AUTOSAR XML (schema 4-2-1)
standard types defined: boolean, uint16, uint8
package /VehicleProject
  system System
package /NM
  nm config NmConfig: can-nm-cluster-coupling=coupled-cluster=CAN00_CAN
    can nm cluster CAN00_CAN: communication-cluster=Comfort, nm-channel-id=0, nm-msg-cycle-time=2, nm-network-timeout=1, nm-repeat-message-time=0.4, nm-user-data-length=5, nm-wait-bus-sleep-time=0.75
      4 x can nm node, all with nm-msg-cycle-offset=0.01, nm-msg-reduced-time=0.05, nm-range-config={lower-can-id=1280, upper-can-id=1407}:
        Console: controller=Console/CT_CAN00, nm-if-ecu=Console_CAN, nm-node-id=-230, tx-nm-pdu=NM_Console
        DOOR_le: controller=DOOR_le/CT_CAN00, nm-if-ecu=DOOR_le_CAN, nm-node-id=-229, rx-nm-pdu=[NM_Console, NM_DOORright, NM_Gateway], tx-nm-pdu=NM_DOORleft
        DOOR_ri: controller=DOOR_ri/CT_CAN00, nm-if-ecu=DOOR_ri_CAN, nm-node-id=-228, rx-nm-pdu=[NM_Console, NM_DOORleft, NM_Gateway], tx-nm-pdu=NM_DOORright
        Gateway: controller=Gateway/CT_CAN00, nm-if-ecu=Gateway_CAN, nm-node-id=-227, rx-nm-pdu=[NM_Console, NM_DOORleft, NM_DOORright], tx-nm-pdu=NM_Gateway
    nm-if-ecus:
      4 x nm ecu, all with nm-node-id-enabled=true, nm-user-data-enabled=true:
        Console_CAN: ecu-instance=Console
        DOOR_le_CAN: ecu-instance=DOOR_le
        DOOR_ri_CAN: ecu-instance=DOOR_ri
        Gateway_CAN: ecu-instance=Gateway
package /TP
  can tp config CAN00_CAN: communication-cluster=Comfort
    can tp channel TPCH: channel-id=0, channel-mode=FULL-DUPLEX-MODE
package /Cluster
  can cluster Comfort: baudrate=500000, protocol-name=CAN  # democomfort | CAN communication matrix for body electronics*******************************************************implemented: turn lights, warning lights, windows
    can physical channel CHNL: comm-connectors=[Console/CN_CAN00, Dashboard/CN_CAN00, DOOR_le/CN_CAN00, DOOR_ri/CN_CAN00, Gateway/CN_CAN00]
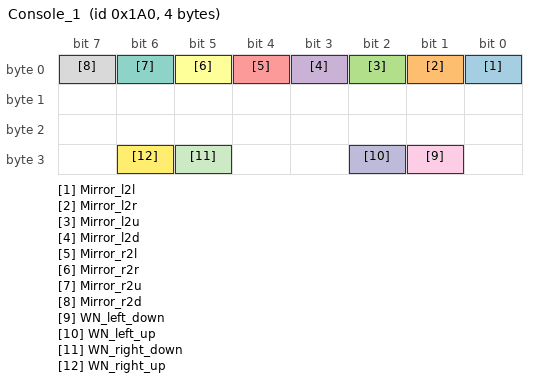
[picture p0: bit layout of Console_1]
      frame Console_1: id 0x1A0, from Console, to DOOR_le DOOR_ri, frame-length=4, can-addressing-mode=STANDARD, can-frame-tx-behavior=CAN-20
        pdu Console_1: length=4, minimum-delay=0.001, transmission-mode-false-timing=cyclic-timing={time-offset=0, time-period=0.02}, transmission-mode-true-timing=cyclic-timing={time-offset=0, time-period=0.02}, unused-bit-pattern=0
          signal Mirror_l2l: start 0, 1 bit, little-endian, init-value=0, base-type=boolean, compu {phys=raw for raw 0..1}, transfer-property=PENDING
          signal Mirror_l2r: start 1, 1 bit, little-endian, init-value=0, base-type=boolean, compu {phys=raw for raw 0..1}, transfer-property=PENDING
          signal Mirror_l2u: start 2, 1 bit, little-endian, init-value=0, base-type=boolean, compu {phys=raw for raw 0..1}, transfer-property=PENDING
          signal Mirror_l2d: start 3, 1 bit, little-endian, init-value=0, base-type=boolean, compu {phys=raw for raw 0..1}, transfer-property=PENDING
          signal Mirror_r2l: start 4, 1 bit, little-endian, init-value=0, base-type=boolean, compu {phys=raw for raw 0..1}, transfer-property=PENDING
          signal Mirror_r2r: start 5, 1 bit, little-endian, init-value=0, base-type=boolean, compu {phys=raw for raw 0..1}, transfer-property=PENDING
          signal Mirror_r2u: start 6, 1 bit, little-endian, init-value=0, base-type=boolean, compu {phys=raw for raw 0..1}, transfer-property=PENDING
          signal Mirror_r2d: start 7, 1 bit, little-endian, init-value=0, base-type=boolean, compu {phys=raw for raw 0..1}, transfer-property=PENDING
          signal WN_left_down: start 25, 1 bit, little-endian, init-value=0, base-type=boolean, compu {phys=raw for raw 0..1}, transfer-property=PENDING, to DOOR_le
          signal WN_left_up: start 26, 1 bit, little-endian, init-value=0, base-type=boolean, compu {phys=raw for raw 0..1}, transfer-property=PENDING, to DOOR_le
          signal WN_right_down: start 29, 1 bit, little-endian, init-value=0, base-type=boolean, compu {phys=raw for raw 0..1}, transfer-property=PENDING, to DOOR_ri
          signal WN_right_up: start 30, 1 bit, little-endian, init-value=0, base-type=boolean, compu {phys=raw for raw 0..1}, transfer-property=PENDING, to DOOR_ri
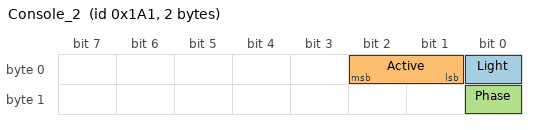
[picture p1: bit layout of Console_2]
      frame Console_2: id 0x1A1, from Console, frame-length=2, can-addressing-mode=STANDARD, can-frame-tx-behavior=CAN-20
        pdu Console_2: length=2, minimum-delay=0.001, transmission-mode-condition{data-filter={data-filter-type=MASKED-NEW-DIFFERS-X, mask=1, x=0}, i-signal-in-i-pdu=Light}, transmission-mode-false-timing=cyclic-timing=time-period=0.5, transmission-mode-true-timing=cyclic-timing=time-period=0.1, unused-bit-pattern=0
          signal Light: start 0, 1 bit, little-endian, init-value=0, base-type=boolean, compu {phys=raw for raw 0..1}, transfer-property=PENDING
          signal Active: start 1, 2 bit, little-endian, init-value=0, base-type=uint8, compu {0=None, 1=Turn_right, 2=Turn_left, 3=Warning}, transfer-property=PENDING
          signal Phase: start 8, 1 bit, little-endian, init-value=0, base-type=boolean, compu {phys=raw for raw 0..1}, transfer-property=PENDING
      frame DebugMsg1: id 0x100, to Gateway, frame-length=8, can-addressing-mode=STANDARD, can-frame-tx-behavior=CAN-20
        pdu DebugMsg1: length=8, minimum-delay=0, unused-bit-pattern=0
          signal DebugMsg1: start 0, 64 bit, opaque, init-value=8 x 0, base-type=uint8_8_iso_8859_1, compu {phys=raw for raw 0..1.84467440737096e+19}, transfer-property=PENDING, to Gateway
      frame Diag_Request: id 0x700, frame-length=8, can-addressing-mode=STANDARD
      frame Diag_Response: id 0x600, frame-length=8, can-addressing-mode=STANDARD
        user defined pdu Diag_Response: length=8
      frame DiagRequest: id 0x606, to DOOR_le, frame-length=8, can-addressing-mode=STANDARD
        user defined pdu DiagRequest: length=8
      frame DiagResponse_DoorLeft: id 0x607, from DOOR_le, frame-length=8, can-addressing-mode=STANDARD
        user defined pdu DiagResponse_DoorLeft: length=8
      frame DiagResponse_Motor: id 0x601, from Gateway, frame-length=8, can-addressing-mode=STANDARD
        user defined pdu DiagResponse_Motor: length=8
      frame DOOR_l: id 0x1F0, from DOOR_le, frame-length=1, can-addressing-mode=STANDARD, can-frame-tx-behavior=CAN-20
        pdu DOOR_l: length=1, minimum-delay=0.001, transmission-mode-false-timing=cyclic-timing=time-period=0.03, transmission-mode-true-timing=cyclic-timing=time-period=0.03, unused-bit-pattern=0
          signal WN_Position_l: start 0, 8 bit, little-endian, init-value=0, base-type=uint8, compu {phys=raw for raw 0..255}, transfer-property=PENDING
      frame DOOR_r: id 0x1F1, from DOOR_ri, frame-length=1, can-addressing-mode=STANDARD, can-frame-tx-behavior=CAN-20
        pdu DOOR_r: length=1, minimum-delay=0.001, transmission-mode-false-timing=cyclic-timing=time-period=0.03, transmission-mode-true-timing=cyclic-timing=time-period=0.03, unused-bit-pattern=0
          signal WN_Position_r: start 0, 8 bit, little-endian, init-value=0, base-type=uint8, compu {phys=raw for raw 0..255}, transfer-property=PENDING
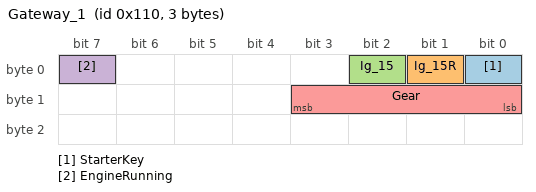
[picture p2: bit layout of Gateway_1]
      frame Gateway_1: id 0x110, from Gateway, to Console Dashboard, frame-length=3, can-addressing-mode=STANDARD, can-frame-tx-behavior=CAN-20
        pdu Gateway_1: length=3, minimum-delay=0.001, transmission-mode-false-timing=cyclic-timing=time-period=0.1, transmission-mode-true-timing=cyclic-timing=time-period=0.1, unused-bit-pattern=0
          signal StarterKey: start 0, 1 bit, little-endian, init-value=0, base-type=boolean, compu {phys=raw for raw 0..1}, transfer-property=PENDING, to Dashboard
          signal Ig_15R: start 1, 1 bit, little-endian, init-value=0, base-type=boolean, compu {phys=raw for raw 0..1}, transfer-property=PENDING, to Dashboard
          signal Ig_15: start 2, 1 bit, little-endian, init-value=0, base-type=boolean, compu {phys=raw for raw 0..1}, transfer-property=PENDING, to Console Dashboard
          signal EngineRunning: start 7, 1 bit, little-endian, init-value=0, base-type=boolean, compu {phys=raw for raw 0..1}, transfer-property=PENDING
          signal Gear: start 8, 4 bit, little-endian, init-value=0, base-type=uint8, compu {phys=raw for raw 0..15}, transfer-property=PENDING, to Dashboard
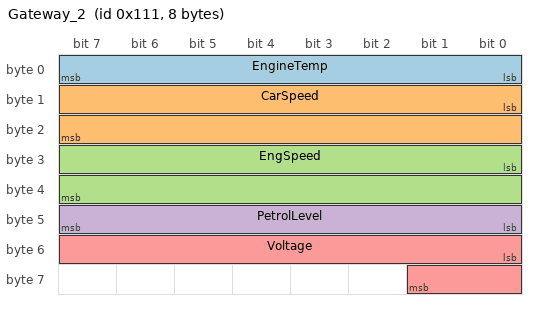
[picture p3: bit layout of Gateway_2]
      frame Gateway_2: id 0x111, from Gateway, to Dashboard, frame-length=8, can-addressing-mode=STANDARD, can-frame-tx-behavior=CAN-20
        pdu Gateway_2: length=8, minimum-delay=0.001, transmission-mode-false-timing={cyclic-timing=time-period=0.1, event-controlled-timing={number-of-repetitions=0, repetition-period=0}}, transmission-mode-true-timing={cyclic-timing=time-period=0.1, event-controlled-timing={number-of-repetitions=0, repetition-period=0}}, unused-bit-pattern=0
          transmission-mode-conditions:
            {data-filter={data-filter-type=MASKED-NEW-DIFFERS-MASKED-OLD, mask=65535}, i-signal-in-i-pdu=CarSpeed}
            {data-filter={data-filter-type=MASKED-NEW-DIFFERS-MASKED-OLD, mask=255}, i-signal-in-i-pdu=EngineTemp}
            {data-filter={data-filter-type=MASKED-NEW-DIFFERS-MASKED-OLD, mask=65535}, i-signal-in-i-pdu=EngSpeed}
            {data-filter={data-filter-type=MASKED-NEW-DIFFERS-MASKED-OLD, mask=255}, i-signal-in-i-pdu=PetrolLevel}
            {data-filter={data-filter-type=MASKED-NEW-DIFFERS-MASKED-OLD, mask=1023}, i-signal-in-i-pdu=Voltage}
          signal EngineTemp: start 0, 8 bit, little-endian, init-value=0, base-type=uint8, compu {phys=raw for raw 0..255; unit degC}, transfer-property=TRIGGERED, to Dashboard
          signal CarSpeed: start 8, 16 bit, little-endian, init-value=0, base-type=uint16, compu {phys=raw*0.5 for raw 0..65535; unit mph}, transfer-property=TRIGGERED, to Dashboard
          signal EngSpeed: start 24, 16 bit, little-endian, init-value=0, base-type=uint16, compu {phys=raw for raw 0..65535; unit rpm}, transfer-property=TRIGGERED, to Dashboard
          signal PetrolLevel: start 40, 8 bit, little-endian, init-value=0, base-type=uint8, compu {phys=raw for raw 0..255; unit l}, transfer-property=TRIGGERED, to Dashboard
          signal Voltage: start 48, 10 bit, little-endian, init-value=0, base-type=uint16, compu {phys=raw*0.1 for raw 0..1023; unit V}, transfer-property=TRIGGERED
      frame NM_Console: id 0x41A, from Console, to DOOR_le DOOR_ri Gateway Dashboard, frame-length=4, can-addressing-mode=STANDARD, can-frame-tx-behavior=CAN-20
        nm pdu NM_Console: length=4, unused-bit-pattern=0
      frame NM_DOORleft: id 0x41B, from DOOR_le, to DOOR_ri Gateway Console Dashboard, frame-length=4, can-addressing-mode=STANDARD, can-frame-tx-behavior=CAN-20
        nm pdu NM_DOORleft: length=4, unused-bit-pattern=0
      frame NM_DOORright: id 0x41C, from DOOR_ri, to DOOR_le Gateway Console Dashboard, frame-length=4, can-addressing-mode=STANDARD, can-frame-tx-behavior=CAN-20
        nm pdu NM_DOORright: length=4, unused-bit-pattern=0
      frame NM_Gateway: id 0x41D, from Gateway, to DOOR_le DOOR_ri Console Dashboard, frame-length=4, can-addressing-mode=STANDARD, can-frame-tx-behavior=CAN-20
        nm pdu NM_Gateway: length=4, unused-bit-pattern=0
      frame TP_Console: id 0x604, from Console, to Dashboard, frame-length=6, can-addressing-mode=STANDARD, can-frame-tx-behavior=CAN-20
        pdu TP_Console: length=6, minimum-delay=0, unused-bit-pattern=0
          signal TP_Console: start 0, 48 bit, opaque, init-value=6 x 0, base-type=uint8_6_iso_8859_1, compu {phys=raw for raw 0..281474976710655}, transfer-property=PENDING, to Dashboard
      frame TP_Dashboard: id 0x605, from Dashboard, to Console, frame-length=6, can-addressing-mode=STANDARD, can-frame-tx-behavior=CAN-20
        pdu TP_Dashboard: length=6, minimum-delay=0, unused-bit-pattern=0
          signal TP_Dashboard: start 0, 48 bit, opaque, init-value=6 x 0, base-type=uint8_6_iso_8859_1, compu {phys=raw for raw 0..281474976710655}, transfer-property=PENDING, to Console
package /ECU
  5 x ecu instance:
    Console: associated-com-i-pdu-group=[Console_Rx, Console_Tx]
      can communication controller CT_CAN00: can-controller-attributes=can-controller-configuration-requirements={max-number-of-time-quanta-per-bit=20, max-sample-point=81.25, min-number-of-time-quanta-per-bit=15, min-sample-point=80}
      can communication connector CN_CAN00: comm-controller=Console/CT_CAN00
    Dashboard: associated-com-i-pdu-group=[Dashboard_Rx, Dashboard_Tx]
      can communication controller CT_CAN00: can-controller-attributes=can-controller-configuration-requirements={max-number-of-time-quanta-per-bit=20, max-sample-point=81.25, min-number-of-time-quanta-per-bit=15, min-sample-point=80}
      can communication connector CN_CAN00: comm-controller=Dashboard/CT_CAN00
    DOOR_le: associated-com-i-pdu-group=[DOOR_le_Rx, DOOR_le_Tx]
      can communication controller CT_CAN00: can-controller-attributes=can-controller-configuration-requirements={max-number-of-time-quanta-per-bit=20, max-sample-point=81.25, min-number-of-time-quanta-per-bit=15, min-sample-point=80}
      can communication connector CN_CAN00: comm-controller=DOOR_le/CT_CAN00
    DOOR_ri: associated-com-i-pdu-group=[DOOR_ri_Rx, DOOR_ri_Tx]
      can communication controller CT_CAN00: can-controller-attributes=can-controller-configuration-requirements={max-number-of-time-quanta-per-bit=20, max-sample-point=81.25, min-number-of-time-quanta-per-bit=15, min-sample-point=80}
      can communication connector CN_CAN00: comm-controller=DOOR_ri/CT_CAN00
    Gateway: associated-com-i-pdu-group=[Gateway_Rx, Gateway_Tx]
      can communication controller CT_CAN00: can-controller-attributes=can-controller-configuration-requirements={max-number-of-time-quanta-per-bit=20, max-sample-point=81.25, min-number-of-time-quanta-per-bit=15, min-sample-point=80}
      can communication connector CN_CAN00: comm-controller=Gateway/CT_CAN00
package /IPDUGroup
  10 x i signal i pdu group:
    Console_Rx: communication-direction=IN, i-signal-i-pdus=[Gateway_1, TP_Dashboard]
    Console_Tx: communication-direction=OUT, i-signal-i-pdus=[Console_1, Console_2, TP_Console]
    Dashboard_Rx: communication-direction=IN, i-signal-i-pdus=[Gateway_1, Gateway_2, TP_Console]
    Dashboard_Tx: communication-direction=OUT, i-signal-i-pdus=TP_Dashboard
    DOOR_le_Rx: communication-direction=IN, i-signal-i-pdus=Console_1
    DOOR_le_Tx: communication-direction=OUT, i-signal-i-pdus=DOOR_l
    DOOR_ri_Rx: communication-direction=IN, i-signal-i-pdus=Console_1
    DOOR_ri_Tx: communication-direction=OUT, i-signal-i-pdus=DOOR_r
    Gateway_Rx: communication-direction=IN, i-signal-i-pdus=DebugMsg1
    Gateway_Tx: communication-direction=OUT, i-signal-i-pdus=[Gateway_1, Gateway_2]
package /PDU
  user defined pdu Diag_Request: length=8
package /DataType
  base type uint8_6_iso_8859_1: category=FIXED_LENGTH, base-type-size=48, base-type-encoding=ISO-8859-1
  base type uint8_8_iso_8859_1: category=FIXED_LENGTH, base-type-size=64, base-type-encoding=ISO-8859-1
package /VectorAutosarExplorerGeneratedObjects/PDUS
  dcm i pdu New_PDU: length=8, diag-pdu-type=DIAG-REQUEST
package /VectorAutosarExplorerGeneratedObjects/UNIT
  5 x unit:
    U_degC: display-name=degC
    U_l: display-name=l
    U_mph: display-name=mph
    U_rpm: display-name=rpm
    U_V: display-name=V
